AUTOSAR XML (schema 00046)
package /IoHwAbsDigOut_Inst_package
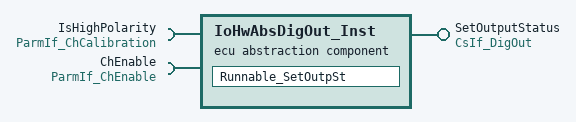
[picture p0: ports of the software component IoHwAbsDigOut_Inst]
  ecu abstraction sw component type IoHwAbsDigOut_Inst
    provide port SetOutputStatus: server-com-spec=CsIf_DigOut_SetSt, provided-interface=CsIf_DigOut
    require port IsHighPolarity: parameter-require-com-spec{init-value=IsHighPoarity_parm:0, parameter=IsHighPoarity_parm}, required-interface=ParmIf_ChCalibration
    require port ChEnable: parameter-require-com-spec{init-value=ChEnable_Parm:0, parameter=ChEnable_Parm}, required-interface=ParmIf_ChEnable
    behavior IoHwAbsDigOut_Inst_internal_behavior
      operation invoked event Operation_Invoked_Event_1_event: start-on-event=Runnable_SetOutpSt, operation=SetOutputStatus.CsIf_DigOut_SetSt
      runnable Runnable_SetOutpSt: can-be-invoked-concurrently=true
        parameter access Runnable_SetOutpSt_ChEnable_ChEnable_Parm: accessed-parameter=ChEnable.ChEnable_Parm
        parameter access Runnable_SetOutpSt_IsHighPolarity_IsHighPoarity_parm: accessed-parameter=IsHighPolarity.IsHighPoarity_parm
